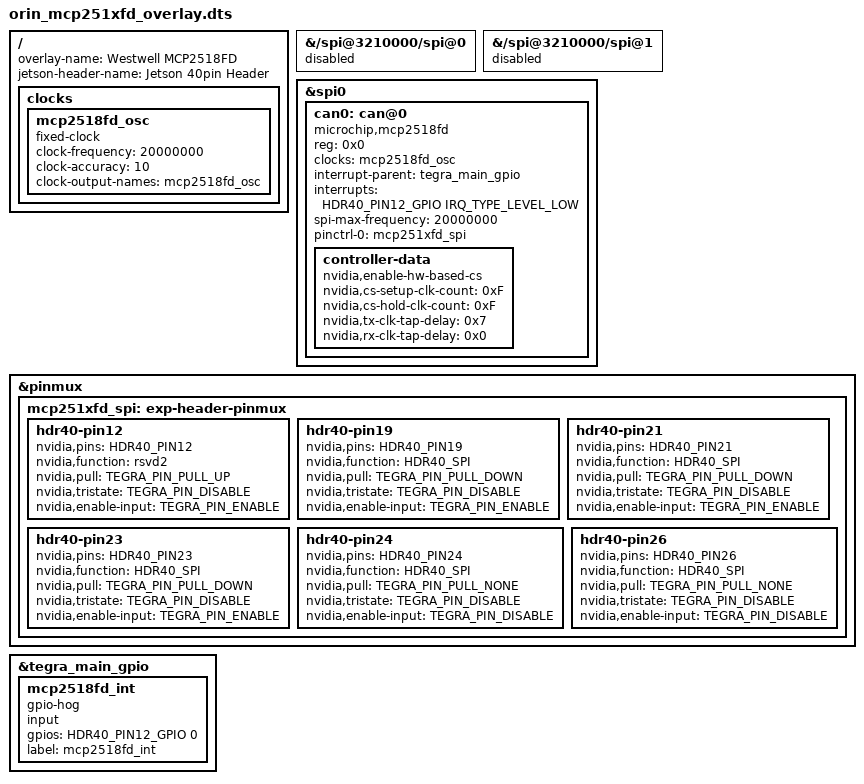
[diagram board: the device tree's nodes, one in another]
/* SPDX-License-Identifier: GPL-2.0-only */



/*
 * Jetson Device-tree overlay for MCP251xFD CAN Controller.
 cpp -nostdinc -I  ./tegra/kernel-include/  -undef -x assembler-with-cpp orin_mcp251xfd_overlay.dts orin_preprocessed.dts
 dtc -@ -I dts -O dtb -o orin_mcp251xfd.dtbo  orin_preprocessed.dts
 */

/dts-v1/;
/plugin/;

#include <dt-common/jetson/tegra234-p3737-0000-p3701-0000.h>
#include <dt-bindings/pinctrl/pinctrl-tegra.h>
#include <dt-bindings/gpio/tegra-gpio.h>
#include <dt-bindings/interrupt-controller/irq.h>

#define TEGRA_MAIN_GPIO(port, offset) TEGRA234_MAIN_GPIO(port, offset)
/ {
	overlay-name = "Westwell MCP2518FD";
	jetson-header-name = "Jetson 40pin Header";	
	compatible = JETSON_COMPATIBLE;

	fragment@0 {
		target-path = "/spi@3210000/spi@0";
		__overlay__ {
			status = "disabled";
		};
	};

	fragment@1{
		target-path = "/spi@3210000/spi@1";
		__overlay__ {
			status = "disabled";
		};
	};

	fragment@2 {
		target-path = "/";
		__overlay__ {
			clocks {
				mcp2518fd_osc: mcp2518fd_osc {
					compatible = "fixed-clock";
					#clock-cells = <0x0>;
					clock-frequency = <20000000>;
					clock-accuracy = <10>;
					clock-output-names = "mcp2518fd_osc";
					status = "okay";
				};
			};
		};
	};

	fragment@3 {
		target = <&spi0>;
		__overlay__ {
			/* avoid dtc warning */
			#address-cells = <1>;
			#size-cells = <0>;
			can0: can@0 {
				compatible = "microchip,mcp2518fd";
				status = "okay";
				/*cs reg addr*/
				reg = <0x0>;
				clocks = <&mcp2518fd_osc>;
				interrupt-parent = <&tegra_main_gpio>;
				interrupts = <HDR40_PIN12_GPIO IRQ_TYPE_LEVEL_LOW>;
				spi-max-frequency = <20000000>;
				pinctrl-names = "default";
			    pinctrl-0 = <&mcp251xfd_spi>;	
				controller-data {
					nvidia,enable-hw-based-cs;
					nvidia,cs-setup-clk-count = <0xF>;
					nvidia,cs-hold-clk-count = <0xF>;
					nvidia,tx-clk-tap-delay = <0x7>;
					nvidia,rx-clk-tap-delay = <0x0>;
				};
			};
		};
	};

	fragment@4 {
		target = <&pinmux>;
		__overlay__ {		
			mcp251xfd_spi: exp-header-pinmux {
				/* mcp251xfd_spi /intr */
				hdr40-pin12 {
					nvidia,pins = HDR40_PIN12;
					nvidia,function = "rsvd2";
					nvidia,pull = <TEGRA_PIN_PULL_UP>;
					nvidia,tristate = <TEGRA_PIN_DISABLE>;
					nvidia,enable-input = <TEGRA_PIN_ENABLE>;
				};				
				hdr40-pin19 {
					nvidia,pins = HDR40_PIN19;
					nvidia,function = HDR40_SPI;
					nvidia,pull = <TEGRA_PIN_PULL_DOWN>;
					nvidia,tristate = <TEGRA_PIN_DISABLE>;
					nvidia,enable-input = <TEGRA_PIN_ENABLE>;
				};
				hdr40-pin21 {
					nvidia,pins = HDR40_PIN21;
					nvidia,function = HDR40_SPI;
					nvidia,pull = <TEGRA_PIN_PULL_DOWN>;
					nvidia,tristate = <TEGRA_PIN_DISABLE>;
					nvidia,enable-input = <TEGRA_PIN_ENABLE>;
				};
				hdr40-pin23 {
					nvidia,pins = HDR40_PIN23;
					nvidia,function = HDR40_SPI;
					nvidia,pull = <TEGRA_PIN_PULL_DOWN>;
					nvidia,tristate = <TEGRA_PIN_DISABLE>;
					nvidia,enable-input = <TEGRA_PIN_ENABLE>;
				};
				/* HDR40_SPI.cs0 */
				hdr40-pin24 {
					nvidia,pins = HDR40_PIN24;
					nvidia,function = HDR40_SPI;
					nvidia,pull = <TEGRA_PIN_PULL_NONE>;
					nvidia,tristate = <TEGRA_PIN_DISABLE>;
					nvidia,enable-input = <TEGRA_PIN_DISABLE>;
				};
				/* HDR40_SPI.cs1 */
				hdr40-pin26 {
					nvidia,pins = HDR40_PIN26;
					nvidia,function = HDR40_SPI;
					nvidia,pull = <TEGRA_PIN_PULL_NONE>;
					nvidia,tristate = <TEGRA_PIN_DISABLE>;
					nvidia,enable-input = <TEGRA_PIN_DISABLE>;
				};
			};
		};
	};

	fragment@5 {
		target = <&tegra_main_gpio>;
		__overlay__ {		
         /* Hog int gpio as Input. */
			mcp2518fd_int {
				gpio-hog;
				input;
				gpios = <HDR40_PIN12_GPIO 0>;
				label = "mcp2518fd_int";
			};
		};
	};

};
